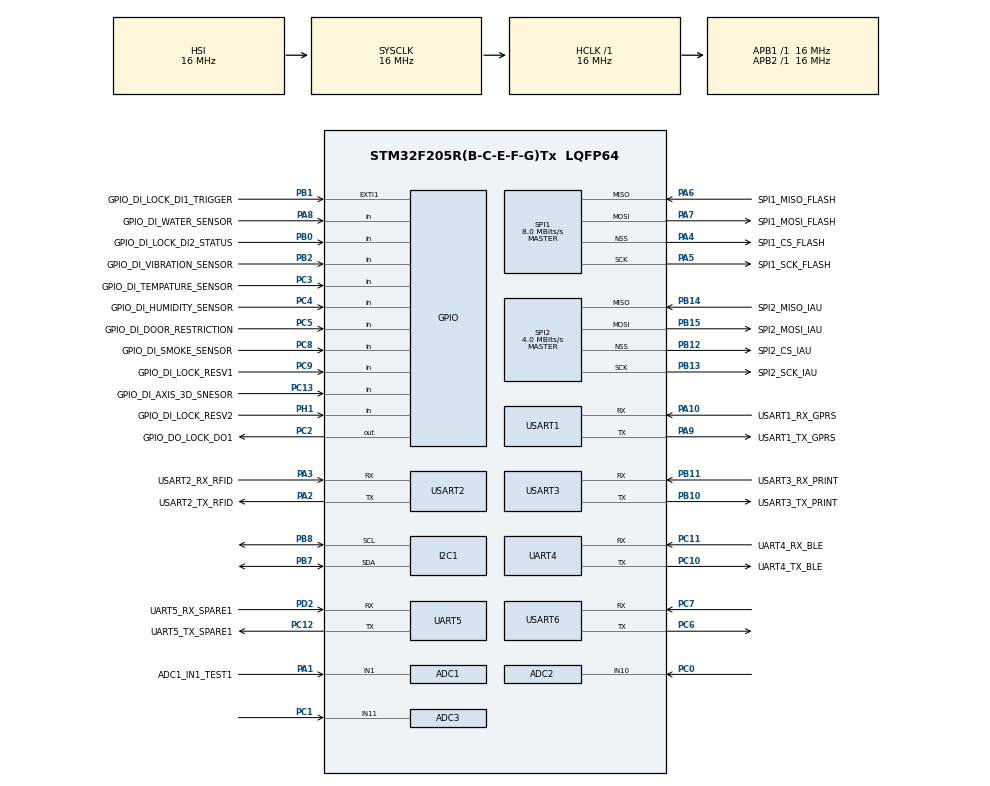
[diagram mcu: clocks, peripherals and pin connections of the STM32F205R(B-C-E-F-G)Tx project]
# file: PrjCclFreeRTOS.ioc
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ADC1.Channel-20\#ChannelRegularConversion=ADC_CHANNEL_1
ADC1.NbrOfConversionFlag=1
ADC1.Rank-20\#ChannelRegularConversion=1
ADC1.SamplingTime-20\#ChannelRegularConversion=ADC_SAMPLETIME_3CYCLES
ADC1.master=1
ADC2.Channel-0\#ChannelRegularConversion=ADC_CHANNEL_10
ADC2.NbrOfConversionFlag=1
ADC2.Rank-0\#ChannelRegularConversion=1
ADC2.SamplingTime-0\#ChannelRegularConversion=ADC_SAMPLETIME_3CYCLES
ADC3.Channel-147\#ChannelRegularConversion=ADC_CHANNEL_11
ADC3.NbrOfConversionFlag=1
ADC3.Rank-147\#ChannelRegularConversion=1
ADC3.SamplingTime-147\#ChannelRegularConversion=ADC_SAMPLETIME_3CYCLES
Dma.Request0=SPI2_RX
Dma.Request1=SPI2_TX
Dma.Request2=SPI1_TX
Dma.Request3=SPI1_RX
Dma.SPI1_RX.3.Direction=DMA_PERIPH_TO_MEMORY
Dma.SPI1_RX.3.FIFOMode=DMA_FIFOMODE_DISABLE
Dma.SPI1_RX.3.Instance=DMA2_Stream0
Dma.SPI1_RX.3.MemDataAlignment=DMA_MDATAALIGN_BYTE
Dma.SPI1_RX.3.MemInc=DMA_MINC_ENABLE
Dma.SPI1_RX.3.Mode=DMA_NORMAL
Dma.SPI1_RX.3.PeriphDataAlignment=DMA_PDATAALIGN_BYTE
Dma.SPI1_RX.3.PeriphInc=DMA_PINC_DISABLE
Dma.SPI1_RX.3.Priority=DMA_PRIORITY_MEDIUM
Dma.SPI1_TX.2.Direction=DMA_MEMORY_TO_PERIPH
Dma.SPI1_TX.2.FIFOMode=DMA_FIFOMODE_DISABLE
Dma.SPI1_TX.2.Instance=DMA2_Stream3
Dma.SPI1_TX.2.MemDataAlignment=DMA_MDATAALIGN_BYTE
Dma.SPI1_TX.2.MemInc=DMA_MINC_ENABLE
Dma.SPI1_TX.2.Mode=DMA_NORMAL
Dma.SPI1_TX.2.PeriphDataAlignment=DMA_PDATAALIGN_BYTE
Dma.SPI1_TX.2.PeriphInc=DMA_PINC_DISABLE
Dma.SPI1_TX.2.Priority=DMA_PRIORITY_MEDIUM
Dma.SPI2_RX.0.Direction=DMA_PERIPH_TO_MEMORY
Dma.SPI2_RX.0.FIFOMode=DMA_FIFOMODE_DISABLE
Dma.SPI2_RX.0.Instance=DMA1_Stream3
Dma.SPI2_RX.0.MemDataAlignment=DMA_MDATAALIGN_BYTE
Dma.SPI2_RX.0.MemInc=DMA_MINC_ENABLE
Dma.SPI2_RX.0.Mode=DMA_NORMAL
Dma.SPI2_RX.0.PeriphDataAlignment=DMA_PDATAALIGN_BYTE
Dma.SPI2_RX.0.PeriphInc=DMA_PINC_DISABLE
Dma.SPI2_RX.0.Priority=DMA_PRIORITY_MEDIUM
Dma.SPI2_TX.1.Direction=DMA_MEMORY_TO_PERIPH
Dma.SPI2_TX.1.FIFOMode=DMA_FIFOMODE_DISABLE
Dma.SPI2_TX.1.Instance=DMA1_Stream4
Dma.SPI2_TX.1.MemDataAlignment=DMA_MDATAALIGN_BYTE
Dma.SPI2_TX.1.MemInc=DMA_MINC_ENABLE
Dma.SPI2_TX.1.Mode=DMA_NORMAL
Dma.SPI2_TX.1.PeriphDataAlignment=DMA_PDATAALIGN_BYTE
Dma.SPI2_TX.1.PeriphInc=DMA_PINC_DISABLE
Dma.SPI2_TX.1.Priority=DMA_PRIORITY_MEDIUM
FREERTOS.INCLUDE_eTaskGetState=1
FREERTOS.INCLUDE_pcTaskGetTaskName=1
FREERTOS.INCLUDE_vTaskCleanUpResources=1
FREERTOS.Queues01=myQueue01,16,uint16_t,NULL
FREERTOS.Tasks01=defaultTask,0,512,StartDefaultTask,Default;myTask02,0,512,StartTask02,Default
FREERTOS.Timers01=myTimer01,Callback01,osTimerPeriodic,Default
FREERTOS.configCHECK_FOR_STACK_OVERFLOW=2
FREERTOS.configGENERATE_RUN_TIME_STATS=1
FREERTOS.configMAX_PRIORITIES=31
FREERTOS.configMAX_TASK_NAME_LEN=24
FREERTOS.configMINIMAL_STACK_SIZE=128
FREERTOS.configQUEUE_REGISTRY_SIZE=2
FREERTOS.configTOTAL_HEAP_SIZE=0x7C00
FREERTOS.configUSE_COUNTING_SEMAPHORES=1
FREERTOS.configUSE_IDLE_HOOK=1
FREERTOS.configUSE_MALLOC_FAILED_HOOK=1
FREERTOS.configUSE_PORT_OPTIMISED_TASK_SELECTION=1
FREERTOS.configUSE_PREEMPTION=1
FREERTOS.configUSE_RECURSIVE_MUTEXES=1
FREERTOS.configUSE_TICKLESS_IDLE=1
FREERTOS.configUSE_TICK_HOOK=1
FREERTOS.configUSE_TIMERS=1
Mcu.Family=STM32F2
Mcu.Name=STM32F205R(B-C-E-F-G)Tx
Mcu.Package=LQFP64
NVIC.DMA1_Stream3_IRQn=true\:5\:0\:false\:false\:true\:true
NVIC.DMA1_Stream4_IRQn=true\:5\:0\:false\:false\:true\:true
NVIC.DMA2_Stream0_IRQn=true\:0\:0\:false\:true\:true\:8\:false
NVIC.DMA2_Stream3_IRQn=true\:0\:0\:false\:true\:true\:9\:false
NVIC.I2C1_ER_IRQn=true\:0\:0\:false\:true\:true\:2\:false
NVIC.I2C1_EV_IRQn=true\:0\:0\:false\:true\:true\:1\:false
NVIC.PriorityGroup=NVIC_PRIORITYGROUP_4
NVIC.SPI2_IRQn=true\:5\:0\:false\:true\:true\:3\:true
NVIC.TIM1_UP_TIM10_IRQn=true\:0\:0\:false\:false\:true\:false
NVIC.TimeBase=TIM1_UP_TIM10_IRQn
NVIC.TimeBaseIP=TIM1
NVIC.UART4_IRQn=true\:5\:0\:false\:true\:true\:6\:true
NVIC.UART5_IRQn=true\:5\:0\:false\:true\:true\:7\:true
NVIC.USART1_IRQn=true\:5\:0\:true\:false\:true\:true
NVIC.USART2_IRQn=true\:5\:0\:false\:true\:true\:4\:true
NVIC.USART3_IRQn=true\:5\:0\:false\:true\:true\:5\:true
NVIC.USART6_IRQn=true\:0\:0\:false\:true\:true\:10\:false
PA0-WKUP.Mode=SYS_WakeUp0
PA0-WKUP.Signal=SYS_WKUP
PA1.GPIO_Label=ADC1_IN1_TEST1
PA1.Signal=ADCx_IN1
PA10.GPIO_Label=USART1_RX_GPRS
PA10.Mode=Asynchronous
PA10.Signal=USART1_RX
PA13.Mode=JTAG_5_pins
PA13.Signal=SYS_JTMS-SWDIO
PA14.Mode=JTAG_5_pins
PA14.Signal=SYS_JTCK-SWCLK
PA15.Mode=JTAG_5_pins
PA15.Signal=SYS_JTDI
PA2.GPIO_Label=USART2_TX_RFID
PA2.Mode=Asynchronous
PA2.Signal=USART2_TX
PA3.GPIO_Label=USART2_RX_RFID
PA3.Mode=Asynchronous
PA3.Signal=USART2_RX
PA4.GPIO_Label=SPI1_CS_FLASH
PA4.Mode=NSS_Signal_Hard_Output
PA4.Signal=SPI1_NSS
PA5.GPIO_Label=SPI1_SCK_FLASH
PA5.Mode=Full_Duplex_Master
PA5.Signal=SPI1_SCK
PA6.GPIO_Label=SPI1_MISO_FLASH
PA6.Mode=Full_Duplex_Master
PA6.Signal=SPI1_MISO
PA7.GPIO_Label=SPI1_MOSI_FLASH
PA7.Mode=Full_Duplex_Master
PA7.Signal=SPI1_MOSI
PA8.GPIO_Label=GPIO_DI_WATER_SENSOR
PA8.Signal=GPIO_Input
PA9.GPIO_Label=USART1_TX_GPRS
PA9.Mode=Asynchronous
PA9.Signal=USART1_TX
PB0.GPIO_Label=GPIO_DI_LOCK_DI2_STATUS
PB0.Signal=GPIO_Input
PB1.GPIO_Label=GPIO_DI_LOCK_DI1_TRIGGER
PB1.Signal=GPXTI1
PB10.GPIO_Label=USART3_TX_PRINT
PB10.Mode=Asynchronous
PB10.Signal=USART3_TX
PB11.GPIO_Label=USART3_RX_PRINT
PB11.Mode=Asynchronous
PB11.Signal=USART3_RX
PB12.GPIO_Label=SPI2_CS_IAU
PB12.Mode=NSS_Signal_Hard_Output
PB12.Signal=SPI2_NSS
PB13.GPIO_Label=SPI2_SCK_IAU
PB13.Mode=Full_Duplex_Master
PB13.Signal=SPI2_SCK
PB14.GPIO_Label=SPI2_MISO_IAU
PB14.Mode=Full_Duplex_Master
PB14.Signal=SPI2_MISO
PB15.GPIO_Label=SPI2_MOSI_IAU
PB15.Mode=Full_Duplex_Master
PB15.Signal=SPI2_MOSI
PB2.GPIO_Label=GPIO_DI_VIBRATION_SENSOR
PB2.Signal=GPIO_Input
PB3.Mode=JTAG_5_pins
PB3.Signal=SYS_JTDO-SWO
PB4.Mode=JTAG_5_pins
PB4.Signal=SYS_JTRST
PB7.Mode=I2C
PB7.Signal=I2C1_SDA
PB8.Mode=I2C
PB8.Signal=I2C1_SCL
PC0.Signal=ADCx_IN10
PC1.Signal=ADCx_IN11
PC10.GPIO_Label=UART4_TX_BLE
PC10.Mode=Asynchronous
PC10.Signal=UART4_TX
PC11.GPIO_Label=UART4_RX_BLE
PC11.Mode=Asynchronous
PC11.Signal=UART4_RX
PC12.GPIO_Label=UART5_TX_SPARE1
PC12.Mode=Asynchronous
PC12.Signal=UART5_TX
PC13.GPIO_Label=GPIO_DI_AXIS_3D_SNESOR
PC13.Signal=GPIO_Input
PC14-OSC32_IN.Mode=LSE-External-Oscillator
PC14-OSC32_IN.Signal=RCC_OSC32_IN
PC15-OSC32_OUT.Mode=LSE-External-Oscillator
PC15-OSC32_OUT.Signal=RCC_OSC32_OUT
PC2.GPIO_Label=GPIO_DO_LOCK_DO1
PC2.Signal=GPIO_Output
PC3.GPIO_Label=GPIO_DI_TEMPATURE_SENSOR
PC3.Signal=GPIO_Input
PC4.GPIO_Label=GPIO_DI_HUMIDITY_SENSOR
PC4.Signal=GPIO_Input
PC5.GPIO_Label=GPIO_DI_DOOR_RESTRICTION
PC5.Signal=GPIO_Input
PC6.Mode=Asynchronous
PC6.Signal=USART6_TX
PC7.Mode=Asynchronous
PC7.Signal=USART6_RX
PC8.GPIO_Label=GPIO_DI_SMOKE_SENSOR
PC8.Signal=GPIO_Input
PC9.GPIO_Label=GPIO_DI_LOCK_RESV1
PC9.Signal=GPIO_Input
PD2.GPIO_Label=UART5_RX_SPARE1
PD2.Mode=Asynchronous
PD2.Signal=UART5_RX
PH1-OSC_OUT.GPIO_Label=GPIO_DI_LOCK_RESV2
PH1-OSC_OUT.Signal=GPIO_Input
ProjectManager.HeapSize=0x200
ProjectManager.StackSize=0x400
ProjectManager.TargetToolchain=MDK-ARM V5
RCC.48MHZClocksFreq_Value=48000000
RCC.AHBFreq_Value=16000000
RCC.APB1Freq_Value=16000000
RCC.APB1TimFreq_Value=16000000
RCC.APB2Freq_Value=16000000
RCC.APB2TimFreq_Value=16000000
RCC.CortexFreq_Value=2000000
RCC.Cortex_Div=SYSTICK_CLKSOURCE_HCLK_DIV8
RCC.HCLKFreq_Value=16000000
RCC.HSE_VALUE=25000000
RCC.HSI_VALUE=16000000
RCC.SYSCLKFreq_VALUE=16000000
RCC.VCOOutputFreq_Value=192000000
SH.ADCx_IN1.0=ADC1_IN1,IN1
SH.ADCx_IN10.0=ADC2_IN10,IN10
SH.ADCx_IN11.0=ADC3_IN11,IN11
SPI1.BaudRatePrescaler=SPI_BAUDRATEPRESCALER_2
SPI1.CalculateBaudRate=8.0 MBits/s
SPI1.Mode=SPI_MODE_MASTER
SPI1.VirtualNSS=VM_NSSHARD
SPI2.BaudRatePrescaler=SPI_BAUDRATEPRESCALER_4
SPI2.CalculateBaudRate=4.0 MBits/s
SPI2.Mode=SPI_MODE_MASTER
SPI2.VirtualNSS=VM_NSSHARD
VP_FREERTOS_VS_ENABLE.Mode=Enabled
VP_SYS_VS_tim1.Mode=TIM1
VP_TIM6_VS_ClockSourceINT.Mode=Enable_Timer
VP_TIM7_VS_ClockSourceINT.Mode=Enable_Timer
board=PrjCclFreeRTOS

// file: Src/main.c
/**
  ******************************************************************************
  * File Name          : main.c
  * Description        : Main program body
  ******************************************************************************
  *
  * Copyright (c) 2016 STMicroelectronics International N.V.
  * All rights reserved.
  *
  * Redistribution and use in source and binary forms, with or without
  * modification, are permitted, provided that the following conditions are met:
  *
  * 1. Redistribution of source code must retain the above copyright notice,
  *    this list of conditions and the following disclaimer.
  * 2. Redistributions in binary form must reproduce the above copyright notice,
  *    this list of conditions and the following disclaimer in the documentation
  *    and/or other materials provided with the distribution.
  * 3. Neither the name of STMicroelectronics nor the names of other
  *    contributors to this software may be used to endorse or promote products
  *    derived from this software without specific written permission.
  * 4. This software, including modifications and/or derivative works of this
  *    software, must execute solely and exclusively on microcontroller or
  *    microprocessor devices manufactured by or for STMicroelectronics.
  * 5. Redistribution and use of this software other than as permitted under
  *    this license is void and will automatically terminate your rights under
  *    this license.
  *
  * THIS SOFTWARE IS PROVIDED BY STMICROELECTRONICS AND CONTRIBUTORS "AS IS"
  * AND ANY EXPRESS, IMPLIED OR STATUTORY WARRANTIES, INCLUDING, BUT NOT
  * LIMITED TO, THE IMPLIED WARRANTIES OF MERCHANTABILITY, FITNESS FOR A
  * PARTICULAR PURPOSE AND NON-INFRINGEMENT OF THIRD PARTY INTELLECTUAL PROPERTY
  * RIGHTS ARE DISCLAIMED TO THE FULLEST EXTENT PERMITTED BY LAW. IN NO EVENT
  * SHALL STMICROELECTRONICS OR CONTRIBUTORS BE LIABLE FOR ANY DIRECT, INDIRECT,
  * INCIDENTAL, SPECIAL, EXEMPLARY, OR CONSEQUENTIAL DAMAGES (INCLUDING, BUT NOT
  * LIMITED TO, PROCUREMENT OF SUBSTITUTE GOODS OR SERVICES; LOSS OF USE, DATA,
  * OR PROFITS; OR BUSINESS INTERRUPTION) HOWEVER CAUSED AND ON ANY THEORY OF
  * LIABILITY, WHETHER IN CONTRACT, STRICT LIABILITY, OR TORT (INCLUDING
  * NEGLIGENCE OR OTHERWISE) ARISING IN ANY WAY OUT OF THE USE OF THIS SOFTWARE,
  * EVEN IF ADVISED OF THE POSSIBILITY OF SUCH DAMAGE.
  *
  ******************************************************************************
  */
#include "main.h"
#include "stm32f2xx_hal.h"
#include "cmsis_os.h"

/* USER CODE BEGIN Includes */
#include "vmfreeoslayer.h"
/* USER CODE END Includes */

ADC_HandleTypeDef hadc1;
ADC_HandleTypeDef hadc2;
ADC_HandleTypeDef hadc3;

I2C_HandleTypeDef hi2c1;

SPI_HandleTypeDef hspi1;
SPI_HandleTypeDef hspi2;
DMA_HandleTypeDef hdma_spi1_tx;
DMA_HandleTypeDef hdma_spi1_rx;
DMA_HandleTypeDef hdma_spi2_rx;
DMA_HandleTypeDef hdma_spi2_tx;

TIM_HandleTypeDef htim6;
TIM_HandleTypeDef htim7;

UART_HandleTypeDef huart4;
UART_HandleTypeDef huart5;
UART_HandleTypeDef huart1;
UART_HandleTypeDef huart2;
UART_HandleTypeDef huart3;
UART_HandleTypeDef huart6;

osThreadId defaultTaskHandle;
osThreadId myTask02Handle;
osMessageQId myQueue01Handle;
osTimerId myTimer01Handle;

/* USER CODE BEGIN PV */
/* Private variables ---------------------------------------------------------*/
uint8_t zIhuUartRxBuffer[6];

/* USER CODE END PV */

void SystemClock_Config(void);
void Error_Handler(void);
static void MX_GPIO_Init(void);
static void MX_DMA_Init(void);
static void MX_ADC1_Init(void);
static void MX_ADC2_Init(void);
static void MX_ADC3_Init(void);
static void MX_I2C1_Init(void);
static void MX_SPI1_Init(void);
static void MX_SPI2_Init(void);
static void MX_UART4_Init(void);
static void MX_UART5_Init(void);
static void MX_USART1_UART_Init(void);
static void MX_USART2_UART_Init(void);
static void MX_USART3_UART_Init(void);
static void MX_USART6_UART_Init(void);
static void MX_TIM6_Init(void);
static void MX_TIM7_Init(void);
void StartDefaultTask(void const * argument);
void StartTask02(void const * argument);
void Callback01(void const * argument);
static void MX_NVIC_Init(void);

/* USER CODE BEGIN PFP */
/* Private function prototypes -----------------------------------------------*/

/* USER CODE END PFP */

int main(void)
{

  /* MCU Configuration----------------------------------------------------------*/

  /* Reset of all peripherals, Initializes the Flash interface and the Systick. */
  HAL_Init();

  /* Configure the system clock */
  SystemClock_Config();

  /* Initialize all configured peripherals */
  MX_GPIO_Init();
  MX_DMA_Init();
  MX_ADC1_Init();
  MX_ADC2_Init();
  MX_ADC3_Init();
  MX_I2C1_Init();
  MX_SPI1_Init();
  MX_SPI2_Init();
  MX_UART4_Init();
  MX_UART5_Init();
  MX_USART1_UART_Init();
  MX_USART2_UART_Init();
  MX_USART3_UART_Init();
  MX_USART6_UART_Init();
  MX_TIM6_Init();
  MX_TIM7_Init();

  /* Initialize interrupts */
  MX_NVIC_Init();

  /* USER CODE BEGIN 2 */
	/* 使能接收，进入中断回调函数 */
  HAL_UART_Receive_IT(&huart1,&zIhuUartRxBuffer[0],1);
  HAL_UART_Receive_IT(&huart2,&zIhuUartRxBuffer[1],1);
  HAL_UART_Receive_IT(&huart3,&zIhuUartRxBuffer[2],1);
  HAL_UART_Receive_IT(&huart4,&zIhuUartRxBuffer[3],1);
  HAL_UART_Receive_IT(&huart5,&zIhuUartRxBuffer[4],1);
  HAL_UART_Receive_IT(&huart6,&zIhuUartRxBuffer[5],1);

  /* USER CODE END 2 */

  /* Create the timer(s) */
  /* definition and creation of myTimer01 */
  osTimerDef(myTimer01, Callback01);
  myTimer01Handle = osTimerCreate(osTimer(myTimer01), osTimerPeriodic, NULL);

  /* Create the thread(s) */
  /* definition and creation of defaultTask */
  osThreadDef(defaultTask, StartDefaultTask, osPriorityNormal, 0, 512);
  defaultTaskHandle = osThreadCreate(osThread(defaultTask), NULL);

  /* definition and creation of myTask02 */
  osThreadDef(myTask02, StartTask02, osPriorityNormal, 0, 512);
  myTask02Handle = osThreadCreate(osThread(myTask02), NULL);

  /* Create the queue(s) */
  /* definition and creation of myQueue01 */
  osMessageQDef(myQueue01, 16, uint16_t);
  myQueue01Handle = osMessageCreate(osMessageQ(myQueue01), NULL);

  /* USER CODE BEGIN RTOS_QUEUES */
  /* add queues, ... */
	//挂载VMFO到这儿
	ihu_vm_main();

  /* USER CODE END RTOS_QUEUES */

  /* Start scheduler */
  osKernelStart();

  /* We should never get here as control is now taken by the scheduler */

  /* Infinite loop */
  while (1)
  {

  }

}

/** System Clock Configuration
*/
void SystemClock_Config(void)
{

  RCC_OscInitTypeDef RCC_OscInitStruct;
  RCC_ClkInitTypeDef RCC_ClkInitStruct;

    /**Initializes the CPU, AHB and APB busses clocks
    */
  RCC_OscInitStruct.OscillatorType = RCC_OSCILLATORTYPE_HSI;
  RCC_OscInitStruct.HSIState = RCC_HSI_ON;
  RCC_OscInitStruct.HSICalibrationValue = 16;
  RCC_OscInitStruct.PLL.PLLState = RCC_PLL_NONE;
  if (HAL_RCC_OscConfig(&RCC_OscInitStruct) != HAL_OK)
  {
    Error_Handler();
  }

    /**Initializes the CPU, AHB and APB busses clocks
    */
  RCC_ClkInitStruct.ClockType = RCC_CLOCKTYPE_HCLK|RCC_CLOCKTYPE_SYSCLK
                              |RCC_CLOCKTYPE_PCLK1|RCC_CLOCKTYPE_PCLK2;
  RCC_ClkInitStruct.SYSCLKSource = RCC_SYSCLKSOURCE_HSI;
  RCC_ClkInitStruct.AHBCLKDivider = RCC_SYSCLK_DIV1;
  RCC_ClkInitStruct.APB1CLKDivider = RCC_HCLK_DIV1;
  RCC_ClkInitStruct.APB2CLKDivider = RCC_HCLK_DIV1;

  if (HAL_RCC_ClockConfig(&RCC_ClkInitStruct, FLASH_LATENCY_0) != HAL_OK)
  {
    Error_Handler();
  }

    /**Configure the Systick interrupt time
    */
  HAL_SYSTICK_Config(HAL_RCC_GetHCLKFreq()/8000);

    /**Configure the Systick
    */
  HAL_SYSTICK_CLKSourceConfig(SYSTICK_CLKSOURCE_HCLK_DIV8);

  /* SysTick_IRQn interrupt configuration */
  HAL_NVIC_SetPriority(SysTick_IRQn, 15, 0);
}

/** NVIC Configuration
*/
static void MX_NVIC_Init(void)
{
  /* I2C1_EV_IRQn interrupt configuration */
  HAL_NVIC_SetPriority(I2C1_EV_IRQn, 0, 0);
  HAL_NVIC_EnableIRQ(I2C1_EV_IRQn);
  /* I2C1_ER_IRQn interrupt configuration */
  HAL_NVIC_SetPriority(I2C1_ER_IRQn, 0, 0);
  HAL_NVIC_EnableIRQ(I2C1_ER_IRQn);
  /* SPI2_IRQn interrupt configuration */
  HAL_NVIC_SetPriority(SPI2_IRQn, 5, 0);
  HAL_NVIC_EnableIRQ(SPI2_IRQn);
  /* USART2_IRQn interrupt configuration */
  HAL_NVIC_SetPriority(USART2_IRQn, 5, 0);
  HAL_NVIC_EnableIRQ(USART2_IRQn);
  /* USART3_IRQn interrupt configuration */
  HAL_NVIC_SetPriority(USART3_IRQn, 5, 0);
  HAL_NVIC_EnableIRQ(USART3_IRQn);
  /* UART4_IRQn interrupt configuration */
  HAL_NVIC_SetPriority(UART4_IRQn, 5, 0);
  HAL_NVIC_EnableIRQ(UART4_IRQn);
  /* UART5_IRQn interrupt configuration */
  HAL_NVIC_SetPriority(UART5_IRQn, 5, 0);
  HAL_NVIC_EnableIRQ(UART5_IRQn);
  /* DMA2_Stream0_IRQn interrupt configuration */
  HAL_NVIC_SetPriority(DMA2_Stream0_IRQn, 0, 0);
  HAL_NVIC_EnableIRQ(DMA2_Stream0_IRQn);
  /* DMA2_Stream3_IRQn interrupt configuration */
  HAL_NVIC_SetPriority(DMA2_Stream3_IRQn, 0, 0);
  HAL_NVIC_EnableIRQ(DMA2_Stream3_IRQn);
  /* USART6_IRQn interrupt configuration */
  HAL_NVIC_SetPriority(USART6_IRQn, 0, 0);
  HAL_NVIC_EnableIRQ(USART6_IRQn);
}

/* ADC1 init function */
static void MX_ADC1_Init(void)
{

  ADC_ChannelConfTypeDef sConfig;

    /**Configure the global features of the ADC (Clock, Resolution, Data Alignment and number of conversion)
    */
  hadc1.Instance = ADC1;
  hadc1.Init.ClockPrescaler = ADC_CLOCK_SYNC_PCLK_DIV2;
  hadc1.Init.Resolution = ADC_RESOLUTION_12B;
  hadc1.Init.ScanConvMode = DISABLE;
  hadc1.Init.ContinuousConvMode = DISABLE;
  hadc1.Init.DiscontinuousConvMode = DISABLE;
  hadc1.Init.ExternalTrigConvEdge = ADC_EXTERNALTRIGCONVEDGE_NONE;
  hadc1.Init.DataAlign = ADC_DATAALIGN_RIGHT;
  hadc1.Init.NbrOfConversion = 1;
  hadc1.Init.DMAContinuousRequests = DISABLE;
  hadc1.Init.EOCSelection = ADC_EOC_SINGLE_CONV;
  if (HAL_ADC_Init(&hadc1) != HAL_OK)
  {
    Error_Handler();
  }

    /**Configure for the selected ADC regular channel its corresponding rank in the sequencer and its sample time.
    */
  sConfig.Channel = ADC_CHANNEL_1;
  sConfig.Rank = 1;
  sConfig.SamplingTime = ADC_SAMPLETIME_3CYCLES;
  if (HAL_ADC_ConfigChannel(&hadc1, &sConfig) != HAL_OK)
  {
    Error_Handler();
  }

}

/* ADC2 init function */
static void MX_ADC2_Init(void)
{

  ADC_ChannelConfTypeDef sConfig;

    /**Configure the global features of the ADC (Clock, Resolution, Data Alignment and number of conversion)
    */
  hadc2.Instance = ADC2;
  hadc2.Init.ClockPrescaler = ADC_CLOCK_SYNC_PCLK_DIV2;
  hadc2.Init.Resolution = ADC_RESOLUTION_12B;
  hadc2.Init.ScanConvMode = DISABLE;
  hadc2.Init.ContinuousConvMode = DISABLE;
  hadc2.Init.DiscontinuousConvMode = DISABLE;
  hadc2.Init.ExternalTrigConvEdge = ADC_EXTERNALTRIGCONVEDGE_NONE;
  hadc2.Init.DataAlign = ADC_DATAALIGN_RIGHT;
  hadc2.Init.NbrOfConversion = 1;
  hadc2.Init.DMAContinuousRequests = DISABLE;
  hadc2.Init.EOCSelection = ADC_EOC_SINGLE_CONV;
  if (HAL_ADC_Init(&hadc2) != HAL_OK)
  {
    Error_Handler();
  }

    /**Configure for the selected ADC regular channel its corresponding rank in the sequencer and its sample time.
    */
  sConfig.Channel = ADC_CHANNEL_10;
  sConfig.Rank = 1;
  sConfig.SamplingTime = ADC_SAMPLETIME_3CYCLES;
  if (HAL_ADC_ConfigChannel(&hadc2, &sConfig) != HAL_OK)
  {
    Error_Handler();
  }

}

/* ADC3 init function */
static void MX_ADC3_Init(void)
{

  ADC_ChannelConfTypeDef sConfig;

    /**Configure the global features of the ADC (Clock, Resolution, Data Alignment and number of conversion)
    */
  hadc3.Instance = ADC3;
  hadc3.Init.ClockPrescaler = ADC_CLOCK_SYNC_PCLK_DIV2;
  hadc3.Init.Resolution = ADC_RESOLUTION_12B;
  hadc3.Init.ScanConvMode = DISABLE;
  hadc3.Init.ContinuousConvMode = DISABLE;
  hadc3.Init.DiscontinuousConvMode = DISABLE;
  hadc3.Init.ExternalTrigConvEdge = ADC_EXTERNALTRIGCONVEDGE_NONE;
  hadc3.Init.DataAlign = ADC_DATAALIGN_RIGHT;
  hadc3.Init.NbrOfConversion = 1;
  hadc3.Init.DMAContinuousRequests = DISABLE;
  hadc3.Init.EOCSelection = ADC_EOC_SINGLE_CONV;
  if (HAL_ADC_Init(&hadc3) != HAL_OK)
  {
    Error_Handler();
  }

    /**Configure for the selected ADC regular channel its corresponding rank in the sequencer and its sample time.
    */
  sConfig.Channel = ADC_CHANNEL_11;
  sConfig.Rank = 1;
  sConfig.SamplingTime = ADC_SAMPLETIME_3CYCLES;
  if (HAL_ADC_ConfigChannel(&hadc3, &sConfig) != HAL_OK)
  {
    Error_Handler();
  }

}

/* I2C1 init function */
static void MX_I2C1_Init(void)
{

  hi2c1.Instance = I2C1;
  hi2c1.Init.ClockSpeed = 100000;
  hi2c1.Init.DutyCycle = I2C_DUTYCYCLE_2;
  hi2c1.Init.OwnAddress1 = 0;
  hi2c1.Init.AddressingMode = I2C_ADDRESSINGMODE_7BIT;
  hi2c1.Init.DualAddressMode = I2C_DUALADDRESS_DISABLE;
  hi2c1.Init.OwnAddress2 = 0;
  hi2c1.Init.GeneralCallMode = I2C_GENERALCALL_DISABLE;
  hi2c1.Init.NoStretchMode = I2C_NOSTRETCH_DISABLE;
  if (HAL_I2C_Init(&hi2c1) != HAL_OK)
  {
    Error_Handler();
  }

}

/* SPI1 init function */
static void MX_SPI1_Init(void)
{

  hspi1.Instance = SPI1;
  hspi1.Init.Mode = SPI_MODE_MASTER;
  hspi1.Init.Direction = SPI_DIRECTION_2LINES;
  hspi1.Init.DataSize = SPI_DATASIZE_8BIT;
  hspi1.Init.CLKPolarity = SPI_POLARITY_LOW;
  hspi1.Init.CLKPhase = SPI_PHASE_1EDGE;
  hspi1.Init.NSS = SPI_NSS_HARD_OUTPUT;
  hspi1.Init.BaudRatePrescaler = SPI_BAUDRATEPRESCALER_2;
  hspi1.Init.FirstBit = SPI_FIRSTBIT_MSB;
  hspi1.Init.TIMode = SPI_TIMODE_DISABLE;
  hspi1.Init.CRCCalculation = SPI_CRCCALCULATION_DISABLE;
  hspi1.Init.CRCPolynomial = 10;
  if (HAL_SPI_Init(&hspi1) != HAL_OK)
  {
    Error_Handler();
  }

}

/* SPI2 init function */
static void MX_SPI2_Init(void)
{

  hspi2.Instance = SPI2;
  hspi2.Init.Mode = SPI_MODE_MASTER;
  hspi2.Init.Direction = SPI_DIRECTION_2LINES;
  hspi2.Init.DataSize = SPI_DATASIZE_8BIT;
  hspi2.Init.CLKPolarity = SPI_POLARITY_LOW;
  hspi2.Init.CLKPhase = SPI_PHASE_1EDGE;
  hspi2.Init.NSS = SPI_NSS_HARD_OUTPUT;
  hspi2.Init.BaudRatePrescaler = SPI_BAUDRATEPRESCALER_4;
  hspi2.Init.FirstBit = SPI_FIRSTBIT_MSB;
  hspi2.Init.TIMode = SPI_TIMODE_DISABLE;
  hspi2.Init.CRCCalculation = SPI_CRCCALCULATION_DISABLE;
  hspi2.Init.CRCPolynomial = 10;
  if (HAL_SPI_Init(&hspi2) != HAL_OK)
  {
    Error_Handler();
  }

}

/* TIM6 init function */
static void MX_TIM6_Init(void)
{

  TIM_MasterConfigTypeDef sMasterConfig;

  htim6.Instance = TIM6;
  htim6.Init.Prescaler = 0;
  htim6.Init.CounterMode = TIM_COUNTERMODE_UP;
  htim6.Init.Period = 0;
  if (HAL_TIM_Base_Init(&htim6) != HAL_OK)
  {
    Error_Handler();
  }

  sMasterConfig.MasterOutputTrigger = TIM_TRGO_RESET;
  sMasterConfig.MasterSlaveMode = TIM_MASTERSLAVEMODE_DISABLE;
  if (HAL_TIMEx_MasterConfigSynchronization(&htim6, &sMasterConfig) != HAL_OK)
  {
    Error_Handler();
  }

}

/* TIM7 init function */
static void MX_TIM7_Init(void)
{

  TIM_MasterConfigTypeDef sMasterConfig;

  htim7.Instance = TIM7;
  htim7.Init.Prescaler = 0;
  htim7.Init.CounterMode = TIM_COUNTERMODE_UP;
  htim7.Init.Period = 0;
  if (HAL_TIM_Base_Init(&htim7) != HAL_OK)
  {
    Error_Handler();
  }

  sMasterConfig.MasterOutputTrigger = TIM_TRGO_RESET;
  sMasterConfig.MasterSlaveMode = TIM_MASTERSLAVEMODE_DISABLE;
  if (HAL_TIMEx_MasterConfigSynchronization(&htim7, &sMasterConfig) != HAL_OK)
  {
    Error_Handler();
  }

}

/* UART4 init function */
static void MX_UART4_Init(void)
{

  huart4.Instance = UART4;
  huart4.Init.BaudRate = 115200;
  huart4.Init.WordLength = UART_WORDLENGTH_8B;
  huart4.Init.StopBits = UART_STOPBITS_1;
  huart4.Init.Parity = UART_PARITY_NONE;
  huart4.Init.Mode = UART_MODE_TX_RX;
  huart4.Init.HwFlowCtl = UART_HWCONTROL_NONE;
  huart4.Init.OverSampling = UART_OVERSAMPLING_16;
  if (HAL_UART_Init(&huart4) != HAL_OK)
  {
    Error_Handler();
  }

}

/* UART5 init function */
static void MX_UART5_Init(void)
{

  huart5.Instance = UART5;
  huart5.Init.BaudRate = 115200;
  huart5.Init.WordLength = UART_WORDLENGTH_8B;
  huart5.Init.StopBits = UART_STOPBITS_1;
  huart5.Init.Parity = UART_PARITY_NONE;
  huart5.Init.Mode = UART_MODE_TX_RX;
  huart5.Init.HwFlowCtl = UART_HWCONTROL_NONE;
  huart5.Init.OverSampling = UART_OVERSAMPLING_16;
  if (HAL_UART_Init(&huart5) != HAL_OK)
  {
    Error_Handler();
  }

}

/* USART1 init function */
static void MX_USART1_UART_Init(void)
{

  huart1.Instance = USART1;
  huart1.Init.BaudRate = 115200;
  huart1.Init.WordLength = UART_WORDLENGTH_8B;
  huart1.Init.StopBits = UART_STOPBITS_1;
  huart1.Init.Parity = UART_PARITY_NONE;
  huart1.Init.Mode = UART_MODE_TX_RX;
  huart1.Init.HwFlowCtl = UART_HWCONTROL_NONE;
  huart1.Init.OverSampling = UART_OVERSAMPLING_16;
  if (HAL_UART_Init(&huart1) != HAL_OK)
  {
    Error_Handler();
  }

}

/* USART2 init function */
static void MX_USART2_UART_Init(void)
{

  huart2.Instance = USART2;
  huart2.Init.BaudRate = 115200;
  huart2.Init.WordLength = UART_WORDLENGTH_8B;
  huart2.Init.StopBits = UART_STOPBITS_1;
  huart2.Init.Parity = UART_PARITY_NONE;
  huart2.Init.Mode = UART_MODE_TX_RX;
  huart2.Init.HwFlowCtl = UART_HWCONTROL_NONE;
  huart2.Init.OverSampling = UART_OVERSAMPLING_16;
  if (HAL_UART_Init(&huart2) != HAL_OK)
  {
    Error_Handler();
  }

}

/* USART3 init function */
static void MX_USART3_UART_Init(void)
{

  huart3.Instance = USART3;
  huart3.Init.BaudRate = 115200;
  huart3.Init.WordLength = UART_WORDLENGTH_8B;
  huart3.Init.StopBits = UART_STOPBITS_1;
  huart3.Init.Parity = UART_PARITY_NONE;
  huart3.Init.Mode = UART_MODE_TX_RX;
  huart3.Init.HwFlowCtl = UART_HWCONTROL_NONE;
  huart3.Init.OverSampling = UART_OVERSAMPLING_16;
  if (HAL_UART_Init(&huart3) != HAL_OK)
  {
    Error_Handler();
  }

}

/* USART6 init function */
static void MX_USART6_UART_Init(void)
{

  huart6.Instance = USART6;
  huart6.Init.BaudRate = 115200;
  huart6.Init.WordLength = UART_WORDLENGTH_8B;
  huart6.Init.StopBits = UART_STOPBITS_1;
  huart6.Init.Parity = UART_PARITY_NONE;
  huart6.Init.Mode = UART_MODE_TX_RX;
  huart6.Init.HwFlowCtl = UART_HWCONTROL_NONE;
  huart6.Init.OverSampling = UART_OVERSAMPLING_16;
  if (HAL_UART_Init(&huart6) != HAL_OK)
  {
    Error_Handler();
  }

}

static void MX_DMA_Init(void)
{
  /* DMA controller clock enable */
  __HAL_RCC_DMA2_CLK_ENABLE();
  __HAL_RCC_DMA1_CLK_ENABLE();

  /* DMA interrupt init */
  /* DMA1_Stream3_IRQn interrupt configuration */
  HAL_NVIC_SetPriority(DMA1_Stream3_IRQn, 5, 0);
  HAL_NVIC_EnableIRQ(DMA1_Stream3_IRQn);
  /* DMA1_Stream4_IRQn interrupt configuration */
  HAL_NVIC_SetPriority(DMA1_Stream4_IRQn, 5, 0);
  HAL_NVIC_EnableIRQ(DMA1_Stream4_IRQn);

}

/** Configure pins as
        * Analog
        * Input
        * Output
        * EVENT_OUT
        * EXTI
*/
static void MX_GPIO_Init(void)
{

  GPIO_InitTypeDef GPIO_InitStruct;

  /* GPIO Ports Clock Enable */
  __HAL_RCC_GPIOC_CLK_ENABLE();
  __HAL_RCC_GPIOH_CLK_ENABLE();
  __HAL_RCC_GPIOA_CLK_ENABLE();
  __HAL_RCC_GPIOB_CLK_ENABLE();
  __HAL_RCC_GPIOD_CLK_ENABLE();

  /*Configure GPIO pins : GPIO_DI_AXIS_3D_SNESOR_Pin GPIO_DI_TEMPATURE_SENSOR_Pin GPIO_DI_HUMIDITY_SENSOR_Pin GPIO_DI_DOOR_RESTRICTION_Pin
                           GPIO_DI_SMOKE_SENSOR_Pin GPIO_DI_LOCK_RESV1_Pin */
  GPIO_InitStruct.Pin = GPIO_DI_AXIS_3D_SNESOR_Pin|GPIO_DI_TEMPATURE_SENSOR_Pin|GPIO_DI_HUMIDITY_SENSOR_Pin|GPIO_DI_DOOR_RESTRICTION_Pin
                          |GPIO_DI_SMOKE_SENSOR_Pin|GPIO_DI_LOCK_RESV1_Pin;
  GPIO_InitStruct.Mode = GPIO_MODE_INPUT;
  GPIO_InitStruct.Pull = GPIO_NOPULL;
  HAL_GPIO_Init(GPIOC, &GPIO_InitStruct);

  /*Configure GPIO pin : GPIO_DI_LOCK_RESV2_Pin */
  GPIO_InitStruct.Pin = GPIO_DI_LOCK_RESV2_Pin;
  GPIO_InitStruct.Mode = GPIO_MODE_INPUT;
  GPIO_InitStruct.Pull = GPIO_NOPULL;
  HAL_GPIO_Init(GPIO_DI_LOCK_RESV2_GPIO_Port, &GPIO_InitStruct);

  /*Configure GPIO pin : GPIO_DO_LOCK_DO1_Pin */
  GPIO_InitStruct.Pin = GPIO_DO_LOCK_DO1_Pin;
  GPIO_InitStruct.Mode = GPIO_MODE_OUTPUT_PP;
  GPIO_InitStruct.Pull = GPIO_NOPULL;
  GPIO_InitStruct.Speed = GPIO_SPEED_FREQ_LOW;
  HAL_GPIO_Init(GPIO_DO_LOCK_DO1_GPIO_Port, &GPIO_InitStruct);

  /*Configure GPIO pins : GPIO_DI_LOCK_DI2_STATUS_Pin GPIO_DI_VIBRATION_SENSOR_Pin */
  GPIO_InitStruct.Pin = GPIO_DI_LOCK_DI2_STATUS_Pin|GPIO_DI_VIBRATION_SENSOR_Pin;
  GPIO_InitStruct.Mode = GPIO_MODE_INPUT;
  GPIO_InitStruct.Pull = GPIO_NOPULL;
  HAL_GPIO_Init(GPIOB, &GPIO_InitStruct);

  /*Configure GPIO pin : GPIO_DI_LOCK_DI1_TRIGGER_Pin */
  GPIO_InitStruct.Pin = GPIO_DI_LOCK_DI1_TRIGGER_Pin;
  GPIO_InitStruct.Mode = GPIO_MODE_IT_RISING;
  GPIO_InitStruct.Pull = GPIO_NOPULL;
  HAL_GPIO_Init(GPIO_DI_LOCK_DI1_TRIGGER_GPIO_Port, &GPIO_InitStruct);

  /*Configure GPIO pin : GPIO_DI_WATER_SENSOR_Pin */
  GPIO_InitStruct.Pin = GPIO_DI_WATER_SENSOR_Pin;
  GPIO_InitStruct.Mode = GPIO_MODE_INPUT;
  GPIO_InitStruct.Pull = GPIO_NOPULL;
  HAL_GPIO_Init(GPIO_DI_WATER_SENSOR_GPIO_Port, &GPIO_InitStruct);

  /*Configure GPIO pin Output Level */
  HAL_GPIO_WritePin(GPIO_DO_LOCK_DO1_GPIO_Port, GPIO_DO_LOCK_DO1_Pin, GPIO_PIN_RESET);

}

/* StartDefaultTask function */
void StartDefaultTask(void const * argument)
{

  /* USER CODE BEGIN 5 */
  /* Infinite loop */
  for(;;)
  {
    osDelay(1000);
		//IhuDebugPrint("TASK01: This is a test!\n");
  }
  /* USER CODE END 5 */
}

/* StartTask02 function */
void StartTask02(void const * argument)
{
  /* USER CODE BEGIN StartTask02 */
  /* Infinite loop */
  for(;;)
  {
    osDelay(1000);
		//IhuDebugPrint("TASK02: This is a test!\n");
  }
  /* USER CODE END StartTask02 */
}

/* Callback01 function */
void Callback01(void const * argument)
{
  /* USER CODE BEGIN Callback01 */
  //IhuDebugPrint("Callback01: This is a test!\n");
  /* USER CODE END Callback01 */
}

void HAL_TIM_PeriodElapsedCallback(TIM_HandleTypeDef *htim)
{
  if (htim->Instance == TIM1) {
    HAL_IncTick();
  }
}

void Error_Handler(void)
{
  while(1)
  {
  }
}

/************************ (C) COPYRIGHT STMicroelectronics *****END OF FILE****/

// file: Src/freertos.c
/**
  ******************************************************************************
  * File Name          : freertos.c
  * Description        : Code for freertos applications
  ******************************************************************************
  *
  * Copyright (c) 2016 STMicroelectronics International N.V.
  * All rights reserved.
  *
  * Redistribution and use in source and binary forms, with or without
  * modification, are permitted, provided that the following conditions are met:
  *
  * 1. Redistribution of source code must retain the above copyright notice,
  *    this list of conditions and the following disclaimer.
  * 2. Redistributions in binary form must reproduce the above copyright notice,
  *    this list of conditions and the following disclaimer in the documentation
  *    and/or other materials provided with the distribution.
  * 3. Neither the name of STMicroelectronics nor the names of other
  *    contributors to this software may be used to endorse or promote products
  *    derived from this software without specific written permission.
  * 4. This software, including modifications and/or derivative works of this
  *    software, must execute solely and exclusively on microcontroller or
  *    microprocessor devices manufactured by or for STMicroelectronics.
  * 5. Redistribution and use of this software other than as permitted under
  *    this license is void and will automatically terminate your rights under
  *    this license.
  *
  * THIS SOFTWARE IS PROVIDED BY STMICROELECTRONICS AND CONTRIBUTORS "AS IS"
  * AND ANY EXPRESS, IMPLIED OR STATUTORY WARRANTIES, INCLUDING, BUT NOT
  * LIMITED TO, THE IMPLIED WARRANTIES OF MERCHANTABILITY, FITNESS FOR A
  * PARTICULAR PURPOSE AND NON-INFRINGEMENT OF THIRD PARTY INTELLECTUAL PROPERTY
  * RIGHTS ARE DISCLAIMED TO THE FULLEST EXTENT PERMITTED BY LAW. IN NO EVENT
  * SHALL STMICROELECTRONICS OR CONTRIBUTORS BE LIABLE FOR ANY DIRECT, INDIRECT,
  * INCIDENTAL, SPECIAL, EXEMPLARY, OR CONSEQUENTIAL DAMAGES (INCLUDING, BUT NOT
  * LIMITED TO, PROCUREMENT OF SUBSTITUTE GOODS OR SERVICES; LOSS OF USE, DATA,
  * OR PROFITS; OR BUSINESS INTERRUPTION) HOWEVER CAUSED AND ON ANY THEORY OF
  * LIABILITY, WHETHER IN CONTRACT, STRICT LIABILITY, OR TORT (INCLUDING
  * NEGLIGENCE OR OTHERWISE) ARISING IN ANY WAY OUT OF THE USE OF THIS SOFTWARE,
  * EVEN IF ADVISED OF THE POSSIBILITY OF SUCH DAMAGE.
  *
  ******************************************************************************
  */

#include "FreeRTOS.h"
#include "task.h"

/* Pre/Post sleep processing prototypes */
void PreSleepProcessing(uint32_t *ulExpectedIdleTime);
void PostSleepProcessing(uint32_t *ulExpectedIdleTime);

/* Hook prototypes */
void configureTimerForRunTimeStats(void);
unsigned long getRunTimeCounterValue(void);
void vApplicationIdleHook(void);
void vApplicationTickHook(void);
void vApplicationStackOverflowHook(xTaskHandle xTask, signed char *pcTaskName);

/* USER CODE BEGIN 1 */
/* Functions needed when configGENERATE_RUN_TIME_STATS is on */
void configureTimerForRunTimeStats(void)
{

}

unsigned long getRunTimeCounterValue(void)
{
return 0;
}
/* USER CODE END 1 */

/* USER CODE BEGIN 2 */
void vApplicationIdleHook( void )
{
   /* vApplicationIdleHook() will only be called if configUSE_IDLE_HOOK is set
   to 1 in FreeRTOSConfig.h. It will be called on each iteration of the idle
   task. It is essential that code added to this hook function never attempts
   to block in any way (for example, call xQueueReceive() with a block time
   specified, or call vTaskDelay()). If the application makes use of the
   vTaskDelete() API function (as this demo application does) then it is also
   important that vApplicationIdleHook() is permitted to return to its calling
   function, because it is the responsibility of the idle task to clean up
   memory allocated by the kernel to any task that has since been deleted. */
}
/* USER CODE END 2 */

/* USER CODE BEGIN 3 */
void vApplicationTickHook( void )
{
   /* This function will be called by each tick interrupt if
   configUSE_TICK_HOOK is set to 1 in FreeRTOSConfig.h. User code can be
   added here, but the tick hook is called from an interrupt context, so
   code must not attempt to block, and only the interrupt safe FreeRTOS API
   functions can be used (those that end in FromISR()). */
}
/* USER CODE END 3 */

/* USER CODE BEGIN 4 */
void vApplicationStackOverflowHook(xTaskHandle xTask, signed char *pcTaskName)
{
   /* Run time stack overflow checking is performed if
   configCHECK_FOR_STACK_OVERFLOW is defined to 1 or 2. This hook function is
   called if a stack overflow is detected. */
}
/* USER CODE END 4 */

/* USER CODE BEGIN PREPOSTSLEEP */
void PreSleepProcessing(uint32_t *ulExpectedIdleTime)
{
/* place for user code */
}

void PostSleepProcessing(uint32_t *ulExpectedIdleTime)
{
/* place for user code */
}
/* USER CODE END PREPOSTSLEEP */

/************************ (C) COPYRIGHT STMicroelectronics *****END OF FILE****/
